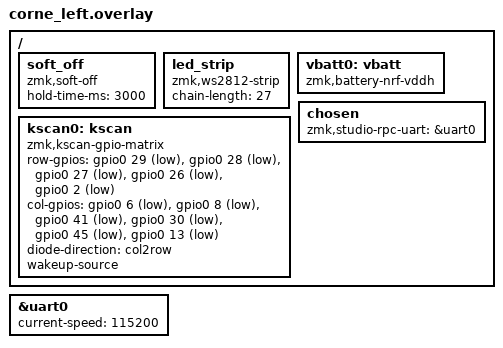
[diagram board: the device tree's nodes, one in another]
/ {
    // Soft off feature (power off on long press)
    soft_off: soft_off {
        compatible = "zmk,soft-off";
        hold-time-ms = <3000>; // 3 seconds hold to power off
    }

    // RGB Underglow (27 LEDs for 34-key Corne)
    led_strip: led_strip {
        compatible = "zmk,ws2812-strip";
        chain-length = <27>;
        // data-pin = <&gpio0 13 GPIO_ACTIVE_HIGH>; // Example, update as needed
    };

    // Battery monitoring
    vbatt0: vbatt {
        compatible = "zmk,battery-nrf-vddh";
    };

    // Key scan matrix for left half
    kscan0: kscan {
        compatible = "zmk,kscan-gpio-matrix";
        row-gpios = <&gpio0 29 GPIO_ACTIVE_LOW>, <&gpio0 28 GPIO_ACTIVE_LOW>, <&gpio0 27 GPIO_ACTIVE_LOW>, <&gpio0 26 GPIO_ACTIVE_LOW>, <&gpio0 2 GPIO_ACTIVE_LOW>;
        col-gpios = <&gpio0 6 GPIO_ACTIVE_LOW>, <&gpio0 8 GPIO_ACTIVE_LOW>, <&gpio0 41 GPIO_ACTIVE_LOW>, <&gpio0 30 GPIO_ACTIVE_LOW>, <&gpio0 45 GPIO_ACTIVE_LOW>, <&gpio0 13 GPIO_ACTIVE_LOW>;
        diode-direction = "col2row";
        wakeup-source;
    };

    chosen {
        zmk,studio-rpc-uart = &uart0;
    };
};

// Enable and configure UART0 for Studio
&uart0 {
    status = "okay";
    current-speed = <115200>;
    // tx-pin = <&gpio0 20 0>; // Example, update as needed
    // rx-pin = <&gpio0 22 0>; // Example, update as needed
};

